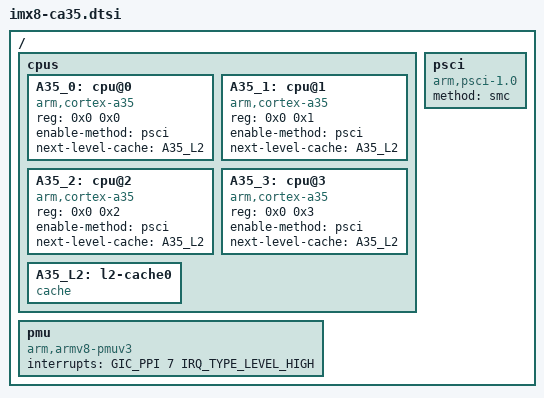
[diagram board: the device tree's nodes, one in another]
// SPDX-License-Identifier: GPL-2.0+
/*
 * Copyright (C) 2016 Freescale Semiconductor, Inc.
 * Copyright 2017~2018 NXP
 */

#include <dt-bindings/interrupt-controller/arm-gic.h>

/{
	cpus {
		#address-cells = <2>;
		#size-cells = <0>;

		/* We have 1 clusters with 4 Cortex-A35 cores */
		A35_0: cpu@0 {
			device_type = "cpu";
			compatible = "arm,cortex-a35";
			reg = <0x0 0x0>;
			enable-method = "psci";
			next-level-cache = <&A35_L2>;
		};

		A35_1: cpu@1 {
			device_type = "cpu";
			compatible = "arm,cortex-a35";
			reg = <0x0 0x1>;
			enable-method = "psci";
			next-level-cache = <&A35_L2>;
		};

		A35_2: cpu@2 {
			device_type = "cpu";
			compatible = "arm,cortex-a35";
			reg = <0x0 0x2>;
			enable-method = "psci";
			next-level-cache = <&A35_L2>;
		};

		A35_3: cpu@3 {
			device_type = "cpu";
			compatible = "arm,cortex-a35";
			reg = <0x0 0x3>;
			enable-method = "psci";
			next-level-cache = <&A35_L2>;
		};

		A35_L2: l2-cache0 {
			compatible = "cache";
		};
	};

	pmu {
		compatible = "arm,armv8-pmuv3";
		interrupts = <GIC_PPI 7 IRQ_TYPE_LEVEL_HIGH>;
	};

	psci {
		compatible = "arm,psci-1.0";
		method = "smc";
	};
};
